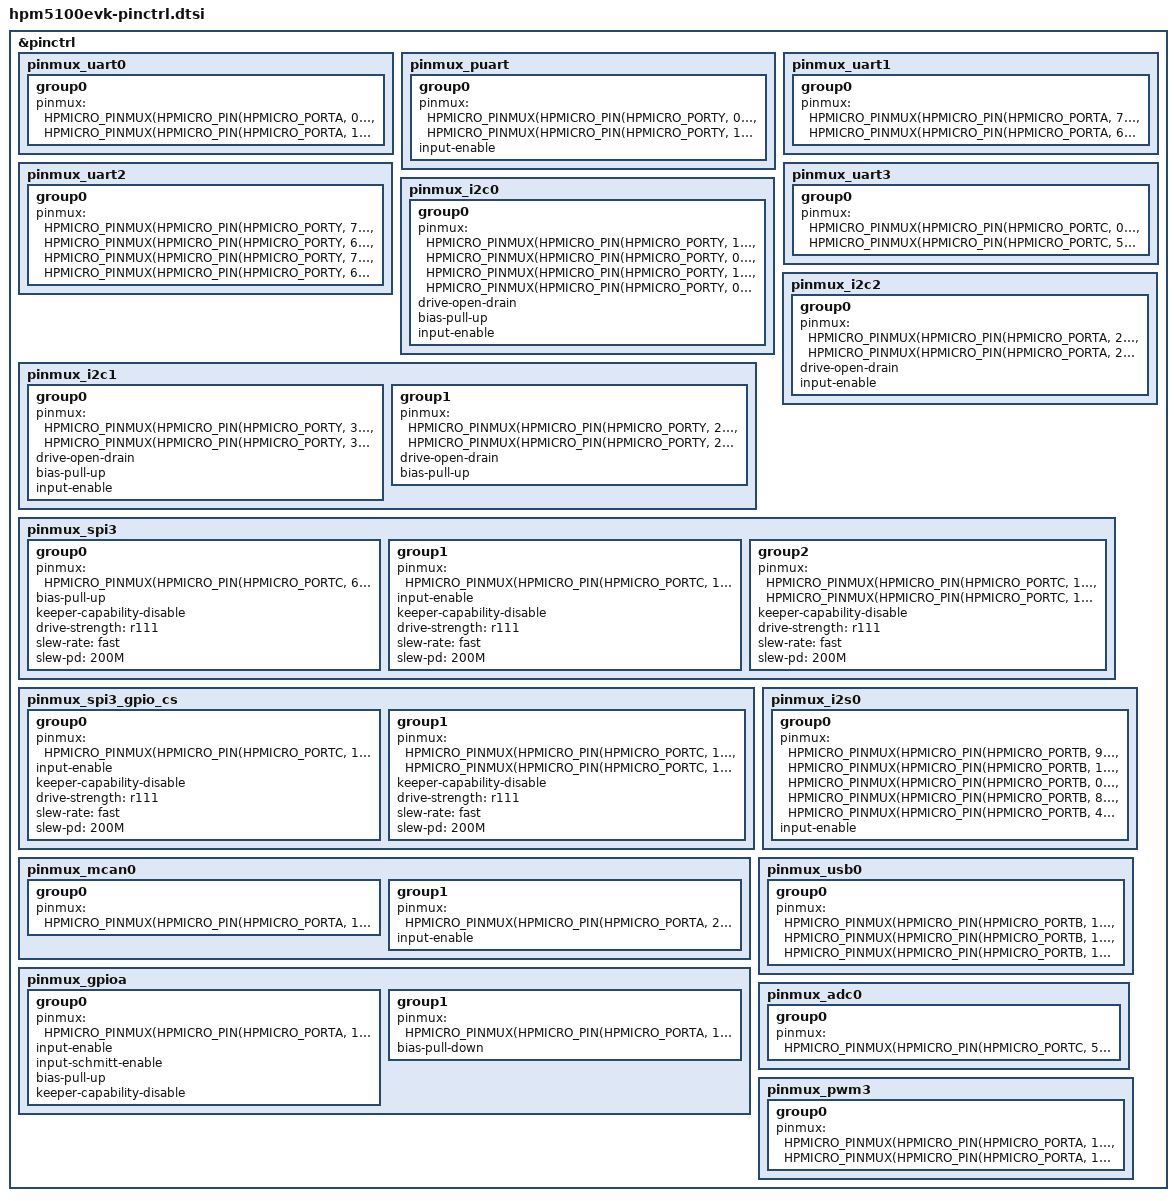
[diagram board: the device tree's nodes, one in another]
/*
 * Copyright 2026 HPMicro
 * SPDX-License-Identifier: Apache-2.0
 */

#include "dt-bindings/pinctrl/hpmicro-pinctrl-common.h"

&pinctrl {
	pinmux_uart0: pinmux_uart0 {
		group0 {
			pinmux = <HPMICRO_PINMUX(HPMICRO_PIN(HPMICRO_PORTA, 0), IOC_TYPE_IOC, 0, 2)>,
					 <HPMICRO_PINMUX(HPMICRO_PIN(HPMICRO_PORTA, 1), IOC_TYPE_IOC, 0, 2)>;
		};
	};

	/*
	 * PMIC-domain PUART: PY00 TX / PY01 RX through PIOC alt1.
	 * These pins cannot be used by SOC I2C0 at the same time.
	 */
	pinmux_puart: pinmux_puart {
		group0 {
			pinmux = <HPMICRO_PINMUX(HPMICRO_PIN(HPMICRO_PORTY, 0), IOC_TYPE_PIOC, 0, 1)>,
					 <HPMICRO_PINMUX(HPMICRO_PIN(HPMICRO_PORTY, 1), IOC_TYPE_PIOC, 0, 1)>;
			input-enable;
		};
	};

	/* UART1: PA07 TX / PA06 RX (alt2). Board default unused. */
	pinmux_uart1: pinmux_uart1 {
		group0 {
			pinmux = <HPMICRO_PINMUX(HPMICRO_PIN(HPMICRO_PORTA, 7), IOC_TYPE_IOC, 0, 2)>,
					 <HPMICRO_PINMUX(HPMICRO_PIN(HPMICRO_PORTA, 6), IOC_TYPE_IOC, 0, 2)>;
		};
	};

	/*
	 * UART2 (SDK BOARD_APP_UART): PY07 TX / PY06 RX + PIOC SOC_GPIO_Y.
	 * TX shares WKUP; high baud may need the WKUP-side capacitor removed.
	 */
	pinmux_uart2: pinmux_uart2 {
		group0 {
			pinmux = <HPMICRO_PINMUX(HPMICRO_PIN(HPMICRO_PORTY, 7), IOC_TYPE_IOC, 0, 2)>,
					 <HPMICRO_PINMUX(HPMICRO_PIN(HPMICRO_PORTY, 6), IOC_TYPE_IOC, 0, 2)>,
					 <HPMICRO_PINMUX(HPMICRO_PIN(HPMICRO_PORTY, 7), IOC_TYPE_PIOC, 0, 3)>,
					 <HPMICRO_PINMUX(HPMICRO_PIN(HPMICRO_PORTY, 6), IOC_TYPE_PIOC, 0, 3)>;
		};
	};

	/* UART3 (SDK LIN sample): PC00 TX / PC05 RX. */
	pinmux_uart3: pinmux_uart3 {
		group0 {
			pinmux = <HPMICRO_PINMUX(HPMICRO_PIN(HPMICRO_PORTC, 0), IOC_TYPE_IOC, 0, 2)>,
					 <HPMICRO_PINMUX(HPMICRO_PIN(HPMICRO_PORTC, 5), IOC_TYPE_IOC, 0, 2)>;
		};
	};

	pinmux_i2c0: pinmux_i2c0 {
		group0 {
			pinmux = <HPMICRO_PINMUX(HPMICRO_PIN(HPMICRO_PORTY, 1), IOC_TYPE_IOC, 0, 4)>,
					 <HPMICRO_PINMUX(HPMICRO_PIN(HPMICRO_PORTY, 0), IOC_TYPE_IOC, 0, 4)>,
					 <HPMICRO_PINMUX(HPMICRO_PIN(HPMICRO_PORTY, 1), IOC_TYPE_PIOC, 0, 3)>,
					 <HPMICRO_PINMUX(HPMICRO_PIN(HPMICRO_PORTY, 0), IOC_TYPE_PIOC, 0, 3)>;
			drive-open-drain;
			bias-pull-up;
			input-enable;
		};
	};

	/* BOARD_APP_I2C = I2C1: PY03 SCL / PY02 SDA (SDK init_i2c1_pins).
	 * SCL needs LOOP_BACK (input-enable); both OD + pull-up like SDK PAD_CTL.
	 */
	pinmux_i2c1: pinmux_i2c1 {
		group0 {
			pinmux = <HPMICRO_PINMUX(HPMICRO_PIN(HPMICRO_PORTY, 3), IOC_TYPE_IOC, 0, 4)>,
					 <HPMICRO_PINMUX(HPMICRO_PIN(HPMICRO_PORTY, 3), IOC_TYPE_PIOC, 0, 3)>;
			drive-open-drain;
			bias-pull-up;
			input-enable;
		};
		group1 {
			pinmux = <HPMICRO_PINMUX(HPMICRO_PIN(HPMICRO_PORTY, 2), IOC_TYPE_IOC, 0, 4)>,
					 <HPMICRO_PINMUX(HPMICRO_PIN(HPMICRO_PORTY, 2), IOC_TYPE_PIOC, 0, 3)>;
			drive-open-drain;
			bias-pull-up;
		};
	};

	pinmux_i2c2: pinmux_i2c2 {
		group0 {
			pinmux = <HPMICRO_PINMUX(HPMICRO_PIN(HPMICRO_PORTA, 23), IOC_TYPE_IOC, 0, 4)>,
					 <HPMICRO_PINMUX(HPMICRO_PIN(HPMICRO_PORTA, 22), IOC_TYPE_IOC, 0, 4)>;
			drive-open-drain;
			input-enable;
		};
	};

	/* SPI3: LOOP_BACK only on SCLK; keeper off; DS=r111 (PC15 ADC load). */
	pinmux_spi3: pinmux_spi3 {
		group0 {
			pinmux = <HPMICRO_PINMUX(HPMICRO_PIN(HPMICRO_PORTC, 6), IOC_TYPE_IOC, 0, 5)>;
			bias-pull-up;
			keeper-capability-disable;
			drive-strength = "r111";
			slew-rate = "fast";
			slew-pd = "200M";
		};
		group1 {
			pinmux = <HPMICRO_PINMUX(HPMICRO_PIN(HPMICRO_PORTC, 10), IOC_TYPE_IOC, 0, 5)>;
			input-enable;
			keeper-capability-disable;
			drive-strength = "r111";
			slew-rate = "fast";
			slew-pd = "200M";
		};
		group2 {
			pinmux = <HPMICRO_PINMUX(HPMICRO_PIN(HPMICRO_PORTC, 13), IOC_TYPE_IOC, 0, 5)>,
					 <HPMICRO_PINMUX(HPMICRO_PIN(HPMICRO_PORTC, 15), IOC_TYPE_IOC, 0, 5)>;
			keeper-capability-disable;
			drive-strength = "r111";
			slew-rate = "fast";
			slew-pd = "200M";
		};
	};

	/* SPI3 data pins only — PC06 used as GPIO CS (SDK init_spi3_pins_with_gpio_as_cs). */
	pinmux_spi3_gpio_cs: pinmux_spi3_gpio_cs {
		group0 {
			pinmux = <HPMICRO_PINMUX(HPMICRO_PIN(HPMICRO_PORTC, 10), IOC_TYPE_IOC, 0, 5)>;
			input-enable;
			keeper-capability-disable;
			drive-strength = "r111";
			slew-rate = "fast";
			slew-pd = "200M";
		};
		group1 {
			pinmux = <HPMICRO_PINMUX(HPMICRO_PIN(HPMICRO_PORTC, 13), IOC_TYPE_IOC, 0, 5)>,
					 <HPMICRO_PINMUX(HPMICRO_PIN(HPMICRO_PORTC, 15), IOC_TYPE_IOC, 0, 5)>;
			keeper-capability-disable;
			drive-strength = "r111";
			slew-rate = "fast";
			slew-pd = "200M";
		};
	};

	pinmux_i2s0: pinmux_i2s0 {
		group0 {
			pinmux = <HPMICRO_PINMUX(HPMICRO_PIN(HPMICRO_PORTB, 9), IOC_TYPE_IOC, 0, 8)>,
					 <HPMICRO_PINMUX(HPMICRO_PIN(HPMICRO_PORTB, 10), IOC_TYPE_IOC, 0, 8)>,
					 <HPMICRO_PINMUX(HPMICRO_PIN(HPMICRO_PORTB, 0), IOC_TYPE_IOC, 0, 8)>,
					 <HPMICRO_PINMUX(HPMICRO_PIN(HPMICRO_PORTB, 8), IOC_TYPE_IOC, 0, 8)>,
					 <HPMICRO_PINMUX(HPMICRO_PIN(HPMICRO_PORTB, 4), IOC_TYPE_IOC, 0, 8)>;
			input-enable;
		};
	};

	/* BOARD_APP_CAN = MCAN0: PA19 TX / PA20 RX (SDK init_can_pins). */
	pinmux_mcan0: pinmux_mcan0 {
		group0 {
			pinmux = <HPMICRO_PINMUX(HPMICRO_PIN(HPMICRO_PORTA, 19), IOC_TYPE_IOC, 0, 7)>;
		};

		group1 {
			pinmux = <HPMICRO_PINMUX(HPMICRO_PIN(HPMICRO_PORTA, 20), IOC_TYPE_IOC, 0, 7)>;
			input-enable;
		};
	};

	pinmux_gpioa: pinmux_gpioa {
		/* USER KEY = PA15 (sdk init_gpio_pins), LED = PA18 */
		group0 {
			pinmux = <HPMICRO_PINMUX(HPMICRO_PIN(HPMICRO_PORTA, 15), IOC_TYPE_IOC, 0, 0)>;
			input-enable;
			input-schmitt-enable;
			bias-pull-up;
			/* PAD_CTL resets with KE=1 and pinctrl_hpmicro.c only clears
			 * KE when this property is present. A to-ground key without
			 * it latches low on the first press (reads as a stuck key,
			 * not as noise) because the keeper fights the pull-up.
			 */
			keeper-capability-disable;
		};

		group1 {
			pinmux = <HPMICRO_PINMUX(HPMICRO_PIN(HPMICRO_PORTA, 18), IOC_TYPE_IOC, 0, 0)>;
			bias-pull-down;
		};
	};

	/*
	 * Match sdk_env HPM5100EVK init_usb0_pins() exactly:
	 * PB13=USB0_ID, PB14=USB0_PWR, PB15=USB0_OC.
	 * PB20/PB21 (USB_DM/DP) are dedicated PHY pads — do not touch IOC.
	 */
	pinmux_usb0: pinmux_usb0 {
		group0 {
			pinmux = <HPMICRO_PINMUX(HPMICRO_PIN(HPMICRO_PORTB, 13), IOC_TYPE_IOC, 0, 25)>,
					 <HPMICRO_PINMUX(HPMICRO_PIN(HPMICRO_PORTB, 14), IOC_TYPE_IOC, 0, 25)>,
					 <HPMICRO_PINMUX(HPMICRO_PIN(HPMICRO_PORTB, 15), IOC_TYPE_IOC, 0, 25)>;
		};
	};

	/* BOARD_APP_ADC16: PC05 = ADC0.IN02 (channel 2) */
	pinmux_adc0: pinmux_adc0 {
		group0 {
			pinmux = <HPMICRO_PINMUX(HPMICRO_PIN(HPMICRO_PORTC, 5), IOC_TYPE_IOC, 1, 0)>;
		};
	};

	/* BOARD_APP_PWM = PWM3: PA16 P_0 / PA17 P_1 (SDK init_pwm3_pins, alt16).
	 * PA18 is board LED (GPIO); do not mux as PWM3_P_2 here.
	 */
	pinmux_pwm3: pinmux_pwm3 {
		group0 {
			pinmux = <HPMICRO_PINMUX(HPMICRO_PIN(HPMICRO_PORTA, 16), IOC_TYPE_IOC, 0, 16)>,
					 <HPMICRO_PINMUX(HPMICRO_PIN(HPMICRO_PORTA, 17), IOC_TYPE_IOC, 0, 16)>;
		};
	};
};
